# jbr_MDR1901VC1T register map
Registers are 32-bit, access not given, no defined reset value unless marked. A register's access mark holds for its fields unless they carry their own. Addresses are absolute; registers are grouped by the start of their names; [hi:lo] are bit positions; {n}, {i} and the like mark numbered series; 'fields as' and 'values as' point back to an identical list.

## MCBSP1
0x30000040 MCBSP1_DRR
  [31:0] DATA_RX
0x30000044 MCBSP1_DXR
  [31:0] DATA_TX
0x30000048 MCBSP1_SPSA
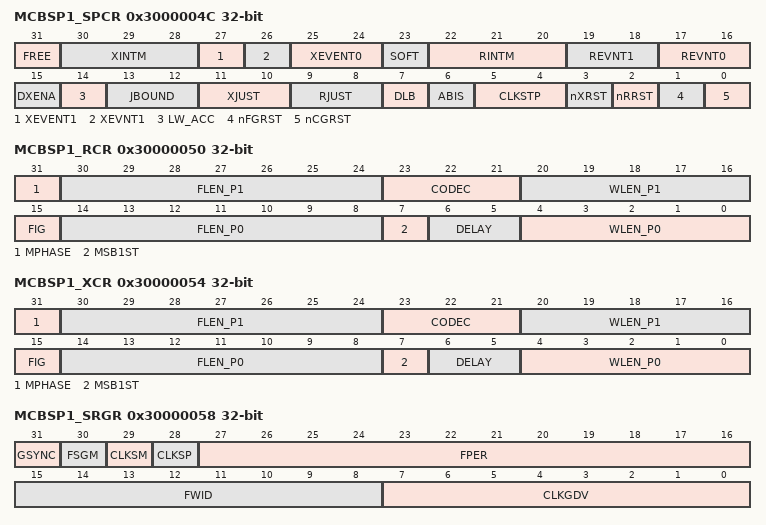
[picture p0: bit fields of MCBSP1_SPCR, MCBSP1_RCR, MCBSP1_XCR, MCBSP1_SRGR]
0x3000004C MCBSP1_SPCR
  [31] FREE, [30:28] XINTM, [27] XEVENT1, [26] XEVNT1, [25:24] XEVENT0, [23] SOFT, [22:20] RINTM, [19:18] REVNT1, [17:16] REVNT0, [15] DXENA, [14] LW_ACC, [13:12] JBOUND, [11:10] XJUST, [9:8] RJUST, [7] DLB, [6] ABIS, [5:4] CLKSTP, [3] nXRST, [2] nRRST, [1] nFGRST, [0] nCGRST
0x30000050 MCBSP1_RCR
  [31] MPHASE, [30:24] FLEN_P1, [23:21] CODEC, [20:16] WLEN_P1, [15] FIG, [14:8] FLEN_P0, [7] MSB1ST, [6:5] DELAY, [4:0] WLEN_P0
0x30000054 MCBSP1_XCR
  fields as MCBSP1_RCR
0x30000058 MCBSP1_SRGR
  [31] GSYNC, [30] FSGM, [29] CLKSM, [28] CLKSP, [27:16] FPER, [15:8] FWID, [7:0] CLKGDV
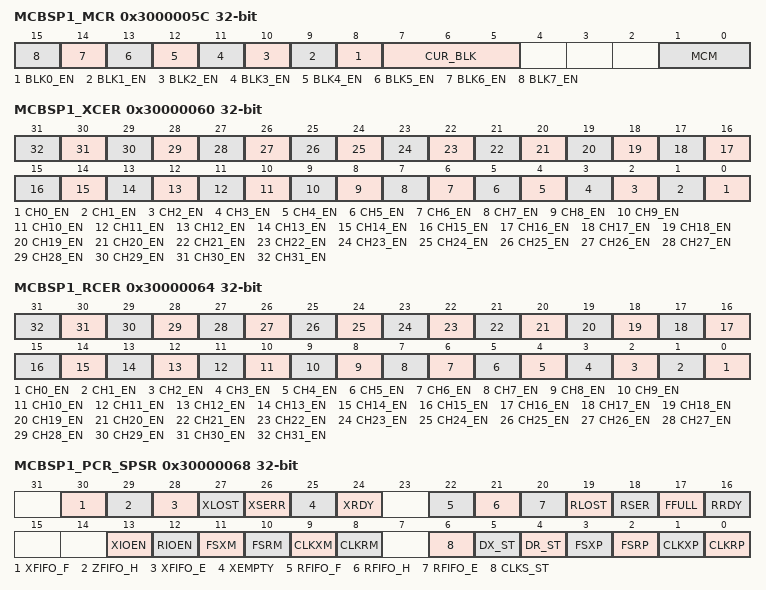
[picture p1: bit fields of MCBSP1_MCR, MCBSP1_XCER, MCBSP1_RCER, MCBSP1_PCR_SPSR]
0x3000005C MCBSP1_MCR
  [n+8] BLK{n}_EN (n=0..7), [7:5] CUR_BLK, [1:0] MCM
0x30000060 MCBSP1_XCER
  [n] CH{n}_EN (n=0..31)
0x30000064 MCBSP1_RCER
  [n] CH{n}_EN (n=0..31)
0x30000068 MCBSP1_PCR_SPSR
  [30] XFIFO_F, [29] ZFIFO_H, [28] XFIFO_E, [27] XLOST, [26] XSERR, [25] XEMPTY, [24] XRDY, [22] RFIFO_F, [21] RFIFO_H, [20] RFIFO_E, [19] RLOST, [18] RSER, [17] FFULL, [16] RRDY, [13] XIOEN, [12] RIOEN, [11] FSXM, [10] FSRM, [9] CLKXM, [8] CLKRM, [6] CLKS_ST, [5] DX_ST, [4] DR_ST, [3] FSXP, [2] FSRP, [1] CLKXP, [0] CLKRP

## MCBSP2
0x30000050 MCBSP2_DRR
  [31:0] DATA_RX
0x30000054 MCBSP2_DXR
  [31:0] DATA_TX
0x30000058 MCBSP2_SPSA
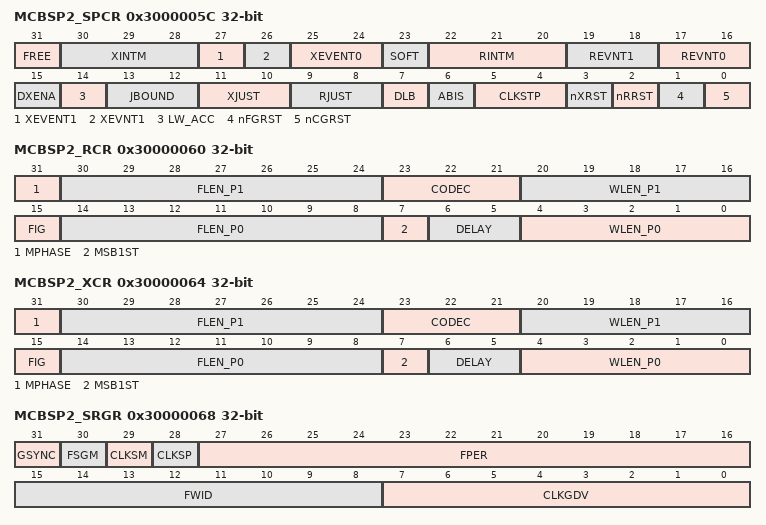
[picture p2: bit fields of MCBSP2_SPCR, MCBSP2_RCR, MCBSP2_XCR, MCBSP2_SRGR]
0x3000005C MCBSP2_SPCR
  [31] FREE, [30:28] XINTM, [27] XEVENT1, [26] XEVNT1, [25:24] XEVENT0, [23] SOFT, [22:20] RINTM, [19:18] REVNT1, [17:16] REVNT0, [15] DXENA, [14] LW_ACC, [13:12] JBOUND, [11:10] XJUST, [9:8] RJUST, [7] DLB, [6] ABIS, [5:4] CLKSTP, [3] nXRST, [2] nRRST, [1] nFGRST, [0] nCGRST
0x30000060 MCBSP2_RCR
  [31] MPHASE, [30:24] FLEN_P1, [23:21] CODEC, [20:16] WLEN_P1, [15] FIG, [14:8] FLEN_P0, [7] MSB1ST, [6:5] DELAY, [4:0] WLEN_P0
0x30000064 MCBSP2_XCR
  fields as MCBSP2_RCR
0x30000068 MCBSP2_SRGR
  [31] GSYNC, [30] FSGM, [29] CLKSM, [28] CLKSP, [27:16] FPER, [15:8] FWID, [7:0] CLKGDV
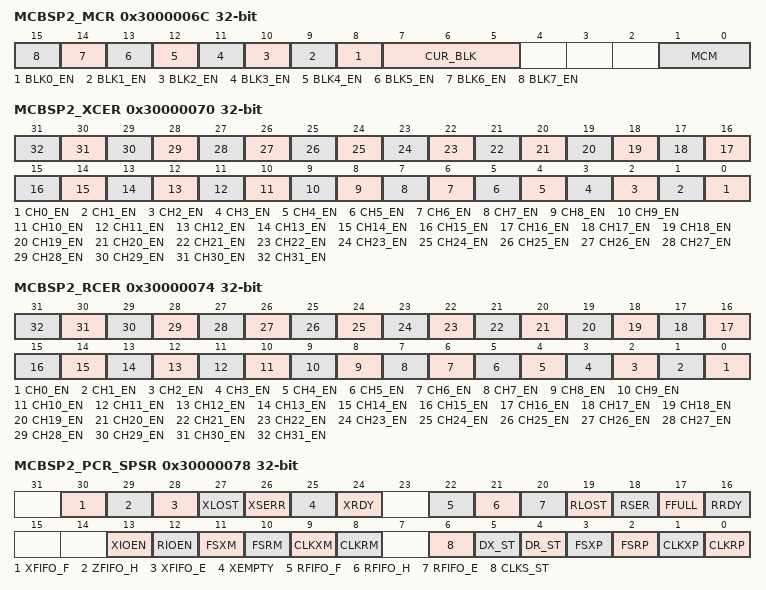
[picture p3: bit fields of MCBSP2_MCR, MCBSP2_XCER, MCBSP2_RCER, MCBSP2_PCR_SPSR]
0x3000006C MCBSP2_MCR
  [n+8] BLK{n}_EN (n=0..7), [7:5] CUR_BLK, [1:0] MCM
0x30000070 MCBSP2_XCER
  [n] CH{n}_EN (n=0..31)
0x30000074 MCBSP2_RCER
  [n] CH{n}_EN (n=0..31)
0x30000078 MCBSP2_PCR_SPSR
  [30] XFIFO_F, [29] ZFIFO_H, [28] XFIFO_E, [27] XLOST, [26] XSERR, [25] XEMPTY, [24] XRDY, [22] RFIFO_F, [21] RFIFO_H, [20] RFIFO_E, [19] RLOST, [18] RSER, [17] FFULL, [16] RRDY, [13] XIOEN, [12] RIOEN, [11] FSXM, [10] FSRM, [9] CLKXM, [8] CLKRM, [6] CLKS_ST, [5] DX_ST, [4] DR_ST, [3] FSXP, [2] FSRP, [1] CLKXP, [0] CLKRP

## MCBSP3
0x30000060 MCBSP3_DRR
  [31:0] DATA_RX
0x30000064 MCBSP3_DXR
  [31:0] DATA_TX
0x30000068 MCBSP3_SPSA
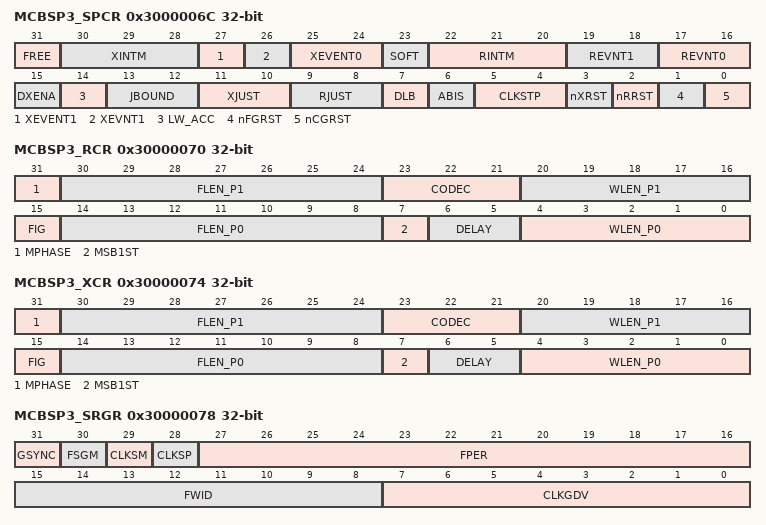
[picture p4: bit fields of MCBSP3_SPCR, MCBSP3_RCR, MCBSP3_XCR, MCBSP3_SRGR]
0x3000006C MCBSP3_SPCR
  [31] FREE, [30:28] XINTM, [27] XEVENT1, [26] XEVNT1, [25:24] XEVENT0, [23] SOFT, [22:20] RINTM, [19:18] REVNT1, [17:16] REVNT0, [15] DXENA, [14] LW_ACC, [13:12] JBOUND, [11:10] XJUST, [9:8] RJUST, [7] DLB, [6] ABIS, [5:4] CLKSTP, [3] nXRST, [2] nRRST, [1] nFGRST, [0] nCGRST
0x30000070 MCBSP3_RCR
  [31] MPHASE, [30:24] FLEN_P1, [23:21] CODEC, [20:16] WLEN_P1, [15] FIG, [14:8] FLEN_P0, [7] MSB1ST, [6:5] DELAY, [4:0] WLEN_P0
0x30000074 MCBSP3_XCR
  fields as MCBSP3_RCR
0x30000078 MCBSP3_SRGR
  [31] GSYNC, [30] FSGM, [29] CLKSM, [28] CLKSP, [27:16] FPER, [15:8] FWID, [7:0] CLKGDV
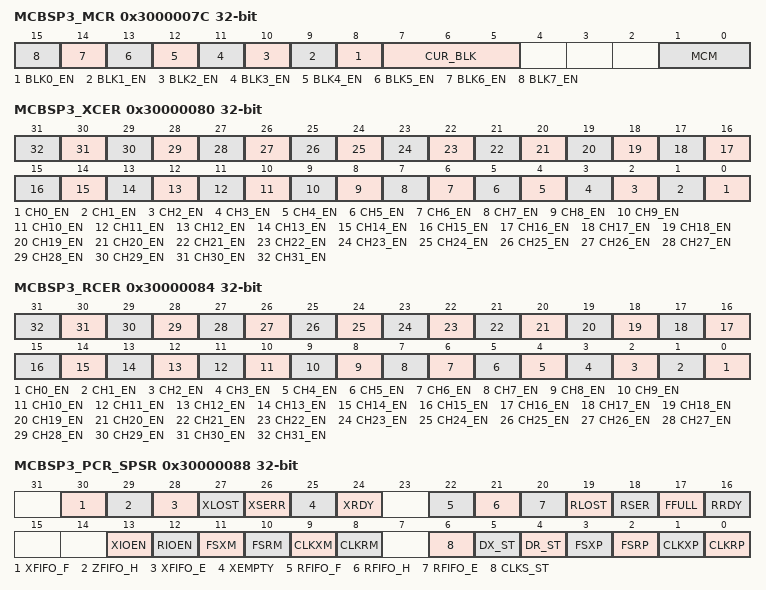
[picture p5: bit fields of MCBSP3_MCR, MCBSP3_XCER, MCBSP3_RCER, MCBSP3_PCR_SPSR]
0x3000007C MCBSP3_MCR
  [n+8] BLK{n}_EN (n=0..7), [7:5] CUR_BLK, [1:0] MCM
0x30000080 MCBSP3_XCER
  [n] CH{n}_EN (n=0..31)
0x30000084 MCBSP3_RCER
  [n] CH{n}_EN (n=0..31)
0x30000088 MCBSP3_PCR_SPSR
  [30] XFIFO_F, [29] ZFIFO_H, [28] XFIFO_E, [27] XLOST, [26] XSERR, [25] XEMPTY, [24] XRDY, [22] RFIFO_F, [21] RFIFO_H, [20] RFIFO_E, [19] RLOST, [18] RSER, [17] FFULL, [16] RRDY, [13] XIOEN, [12] RIOEN, [11] FSXM, [10] FSRM, [9] CLKXM, [8] CLKRM, [6] CLKS_ST, [5] DX_ST, [4] DR_ST, [3] FSXP, [2] FSRP, [1] CLKXP, [0] CLKRP

## SFR
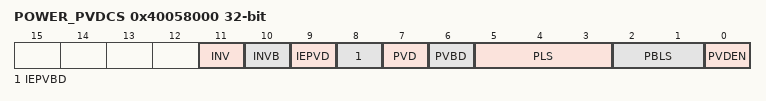
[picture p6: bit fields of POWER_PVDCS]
0x40058000 POWER_PVDCS
  [11] INV, [10] INVB, [9] IEPVD, [8] IEPVBD, [7] PVD, [6] PVBD, [5:3] PLS, [2:1] PBLS, [0] PVDEN
